# TREMO register map
File version: 1.6.2
CPU: CM4 r0p1, little endian, MPU, FPU, 3 interrupt priority bits
Registers are 32-bit, read-write, reset 0x0 unless marked. A register's access mark holds for its fields unless they carry their own. Offsets are from the block's base; [hi:lo] are bit positions; {n}, {i} and the like mark numbered series.

## GPIOA — GPIO
Base 0x4001F000
0x00 OER reset 0xFFFF — output enable register
  [15:0] OEN — Portx Pin[15:0] output enable
0x04 OTYPER — output type register
  [15:0] OTYPE — Portx Pin[15:0] output type control
0x08 IER — input enable register
  [15:0] IE — Portx Pin[15:0] input enable
0x0C PER — pull enable register
  [15:0] PE — Portx Pin[15:0] pull-up/pull-down enable
0x10 PSR — pull select register
  [15:0] PS — Portx Pin[15:0] pull-up/pull-down selection
0x14 IDR ro (reset mask 0xFFFF) — input data register
  [31:0] ID — Portx Pin[15:0] input
0x18 ODR — output data register
  [15:0] OD — Portx Pin[15:0] output
0x1C BRR wo — bit reset register
  [15:0] BR — Portx Pin[15:0] output data clear
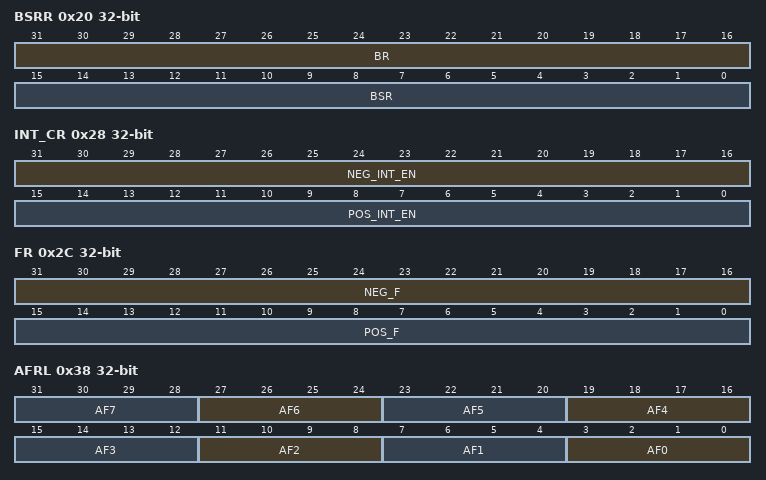
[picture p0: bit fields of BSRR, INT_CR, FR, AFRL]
0x20 BSRR wo — bit set-clear register
  [31:16] BR — Portx Pin[15:0] output data clear
  [15:0] BSR — Portx Pin[15:0] output data set
0x24 DSR wo — drive set register
  [15:0] DS
0x28 INT_CR — interrupt control register
  [31:16] NEG_INT_EN — Portx Pin[15:0] enable interrupt triggered by falling edge
  [15:0] POS_INT_EN — Portx Pin[15:0] enable interrupt triggered by rising edge
0x2C FR — interrupt flag register
  [31:16] NEG_F — Portx Pin[15:0] interrupt flag (falling edge)
  [15:0] POS_F — Portx Pin[15:0] interrupt flag (rising edge)
0x30 WUCR — wakeup control register
  [15:0] WU_EN — Enable/disable Portx Pin[15:0] to wake-up CPU
0x34 WULVL — wakeup level register
  [15:0] WU_LVL — Configure the Portx Pin[15:0] to wakeup CPU
0x38 AFRL — alternate function low register
  [4n+3:4n] AF{n} (n=0..7) — Portx Pin{n} function selection
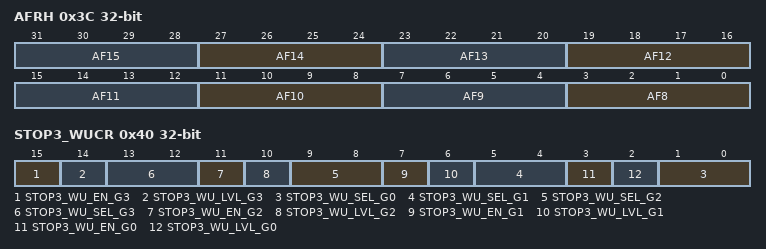
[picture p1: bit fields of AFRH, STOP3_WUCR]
0x3C AFRH — alternate function high register
  [4n-29:4n-32] AF{n} (n=8..15) — Portx Pin{n} function selection
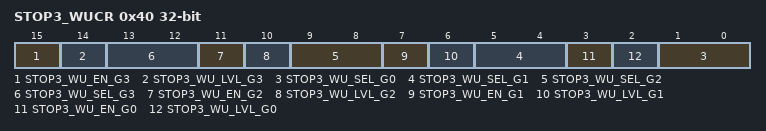
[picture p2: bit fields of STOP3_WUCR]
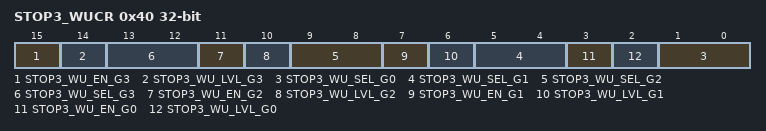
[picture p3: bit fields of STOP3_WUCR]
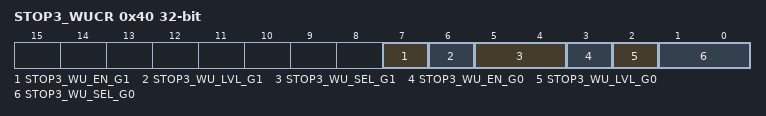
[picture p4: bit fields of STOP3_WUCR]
0x40 STOP3_WUCR — stop3 wakeup control register
  [15] STOP3_WU_EN_G3 — PortA Group3 wake-up pin level selection
  [14] STOP3_WU_LVL_G3 — PortA Group2 wake-up pin level selection
  [4n+1:4n] STOP3_WU_SEL_G{n} (n=0..3) — PortA Pin Group{n} wake-up source selection
  [11] STOP3_WU_EN_G2 — PortA Group1 wake-up pin level selection
  [10] STOP3_WU_LVL_G2 — PortA Group2 wake-up pin level selection
  [7] STOP3_WU_EN_G1 — PortA Group1 wake-up pin level selection
  [6] STOP3_WU_LVL_G1 — PortA Group1 wake-up pin level selection
  [3] STOP3_WU_EN_G0 — PortA Group0 wake-up pin level selection
  [2] STOP3_WU_LVL_G0 — PortA Group0 wake-up pin level selection

## GPIOB — GPIO
Base 0x4001F400
Registers as GPIOA; these are added or differ:
0x40 STOP3_WUCR — stop3 wakeup control register
  [15] STOP3_WU_EN_G3 — PortB Group3 wake-up pin level selection
  [14] STOP3_WU_LVL_G3 — PortB Group2 wake-up pin level selection
  [4n+1:4n] STOP3_WU_SEL_G{n} (n=0..3) — PortB Pin Group{n} wake-up source selection
  [11] STOP3_WU_EN_G2 — PortB Group1 wake-up pin level selection
  [10] STOP3_WU_LVL_G2 — PortB Group2 wake-up pin level selection
  [7] STOP3_WU_EN_G1 — PortB Group1 wake-up pin level selection
  [6] STOP3_WU_LVL_G1 — PortB Group1 wake-up pin level selection
  [3] STOP3_WU_EN_G0 — PortB Group0 wake-up pin level selection
  [2] STOP3_WU_LVL_G0 — PortB Group0 wake-up pin level selection

## GPIOC — GPIO
Base 0x4001F800
Registers as GPIOA; these are added or differ:
0x40 STOP3_WUCR — stop3 wakeup control register
  [15] STOP3_WU_EN_G3 — PortC Group3 wake-up pin level selection
  [14] STOP3_WU_LVL_G3 — PortC Group2 wake-up pin level selection
  [4n+1:4n] STOP3_WU_SEL_G{n} (n=0..3) — PortC Pin Group{n} wake-up source selection
  [11] STOP3_WU_EN_G2 — PortC Group1 wake-up pin level selection
  [10] STOP3_WU_LVL_G2 — PortC Group2 wake-up pin level selection
  [7] STOP3_WU_EN_G1 — PortC Group1 wake-up pin level selection
  [6] STOP3_WU_LVL_G1 — PortC Group1 wake-up pin level selection
  [3] STOP3_WU_EN_G0 — PortC Group0 wake-up pin level selection
  [2] STOP3_WU_LVL_G0 — PortC Group0 wake-up pin level selection

## GPIOD — GPIO
Base 0x4001FC00
Registers as GPIOA; these are added or differ:
0x40 STOP3_WUCR — stop3 wakeup control register
  [7] STOP3_WU_EN_G1 — PortD Group1 wake-up pin level selection
  [6] STOP3_WU_LVL_G1 — PortD Group1 wake-up pin level selection
  [5:4] STOP3_WU_SEL_G1 — PortD Pin Group1 wake-up source selection
  [3] STOP3_WU_EN_G0 — PortD Group0 wake-up pin level selection
  [2] STOP3_WU_LVL_G0 — PortD Group0 wake-up pin level selection
  [1:0] STOP3_WU_SEL_G0 — PortD Pin Group0 wake-up source selection

## Notices in the file
# License
Copyright 2022 Silicon Laboratories Inc. www.silabs.com
SPDX-License-Identifier: Zlib
The licensor of this software is Silicon Laboratories Inc.
This software is provided 'as-is', without any express or implied
warranty. In no event will the authors be held liable for any damages
arising from the use of this software.
Permission is granted to anyone to use this software for any purpose,
including commercial applications, and to alter it and redistribute it
freely, subject to the following restrictions:
1. The origin of this software must not be misrepresented; you must not
claim that you wrote the original software. If you use this software
in a product, an acknowledgment in the product documentation would be
appreciated but is not required.
2. Altered source versions must be plainly marked as such, and must not be
misrepresented as being the original software.
3. This notice may not be removed or altered from any source distribution.
